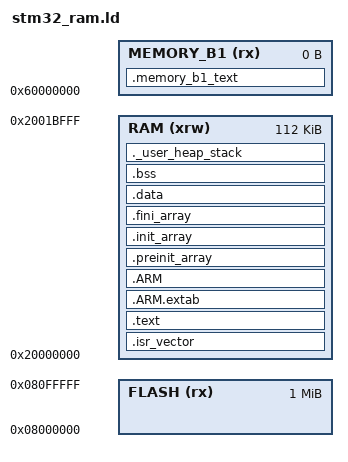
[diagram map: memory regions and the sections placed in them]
/*****************************************************************************
RAM linker
*/

/* Entry Point */
ENTRY(Reset_Handler)

SEARCH_DIR(.)
GROUP(-lgcc -lc)/* -lcs3 -lcs3unhosted -lcs3micro)*/

/* Highest address of the user mode stack */
_estack = 0x2001c000;    /* end of 112K RAM */

/* Generate a link error if heap and stack don't fit into RAM */
/* Heap size 0x1000 */
_Min_Heap_Size = 0x000;      /* required amount of heap  */
_Min_Stack_Size = 0x400; /* required amount of stack */

/* Specify the memory areas */
MEMORY
{
  FLASH (rx)      : ORIGIN = 0x08000000, LENGTH = 1024K /*1024*/
  RAM (xrw)       : ORIGIN = 0x20000000, LENGTH = 112K
  MEMORY_B1 (rx)  : ORIGIN = 0x60000000, LENGTH = 0K
}

/* Define output sections */
SECTIONS
{
  /* The startup code goes first into FLASH */
  .isr_vector :
  {
    . = ALIGN(4);
    KEEP(*(.isr_vector)) /* Startup code */
    . = ALIGN(4);
  } >RAM

  /* The program code and other data goes into FLASH */
  .text :
  {
    . = ALIGN(4);
    *(.text)           /* .text sections (code) */
    *(.text*)          /* .text* sections (code) */
    *(.rodata)         /* .rodata sections (constants, strings, etc.) */
    *(.rodata*)        /* .rodata* sections (constants, strings, etc.) */
    *(.glue_7)         /* glue arm to thumb code */
    *(.glue_7t)        /* glue thumb to arm code */
	*(.eh_frame)

    KEEP (*(.init))
    KEEP (*(.fini))

    . = ALIGN(4);
    _etext = .;        /* define a global symbols at end of code */
  } >RAM


  /* .ARM.extab names a section that contains exception unwinding information.  See EHABI for details. */
  /* .ARM.exidx names a section that contains index entries for section unwinding.  See EHABI for details. */

   .ARM.extab   : { *(.ARM.extab* .gnu.linkonce.armextab.*) } >RAM
    .ARM : {
    __exidx_start = .;
      *(.ARM.exidx*)
      __exidx_end = .;
    } >RAM

  .preinit_array     :
  {
    PROVIDE_HIDDEN (__preinit_array_start = .);
    KEEP (*(.preinit_array*))
    PROVIDE_HIDDEN (__preinit_array_end = .);
  } >RAM
  .init_array :
  {
    PROVIDE_HIDDEN (__init_array_start = .);
    KEEP (*(SORT(.init_array.*)))
    KEEP (*(.init_array*))
    PROVIDE_HIDDEN (__init_array_end = .);
  } >RAM
  .fini_array :
  {
    PROVIDE_HIDDEN (__fini_array_start = .);
    KEEP (*(.fini_array*))
    KEEP (*(SORT(.fini_array.*)))
    PROVIDE_HIDDEN (__fini_array_end = .);
  } >RAM

  /* used by the startup to initialize data */
  _sidata = .;

  /* Initialized data sections goes into RAM, load LMA copy after code */
  .data : AT ( _sidata )
  {
    . = ALIGN(4);
    _sdata = .;        /* create a global symbol at data start */
    *(.data)           /* .data sections */
    *(.data*)          /* .data* sections */

    . = ALIGN(4);
    _edata = .;        /* define a global symbol at data end */
  } >RAM

  /* Uninitialized data section */
  . = ALIGN(4);
  .bss :
  {
    /* This is used by the startup in order to initialize the .bss secion */
    _sbss = .;         /* define a global symbol at bss start */
    __bss_start__ = _sbss;
    *(.bss)
    *(.bss*)
    *(COMMON)

    . = ALIGN(4);
    _ebss = .;         /* define a global symbol at bss end */
    __bss_end__ = _ebss;
  } >RAM

  /* User_heap_stack section, used to check that there is enough RAM left */
  ._user_heap_stack :
  {
    . = ALIGN(4);
    PROVIDE ( end = . );
    PROVIDE ( _end = . );
    . = . + _Min_Heap_Size;
    . = . + _Min_Stack_Size;
    . = ALIGN(4);
  } >RAM

  /* MEMORY_bank1 section, code must be located here explicitly            */
  /* Example: extern int foo(void) __attribute__ ((section (".mb1text"))); */
  .memory_b1_text :
  {
    *(.mb1text)        /* .mb1text sections (code) */
    *(.mb1text*)       /* .mb1text* sections (code)  */
    *(.mb1rodata)      /* read-only data (constants) */
    *(.mb1rodata*)
  } >MEMORY_B1

  /* Remove information from the standard libraries */
  /DISCARD/ :
  {
    libc.a ( * )
    libm.a ( * )
    libgcc.a ( * )
  }

  .ARM.attributes 0 : { *(.ARM.attributes) }

}
